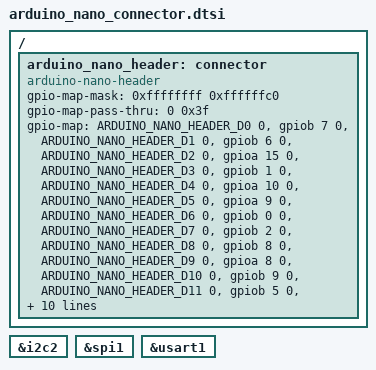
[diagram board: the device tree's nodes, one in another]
/*
 * Copyright (c) 2022 Joylab AG
 * SPDX-License-Identifier: Apache-2.0
 */

#include <zephyr/dt-bindings/gpio/arduino-nano-header.h>

/ {
	arduino_nano_header: connector {
		compatible = "arduino-nano-header";
		#gpio-cells = <2>;
		gpio-map-mask = <0xffffffff 0xffffffc0>;
		gpio-map-pass-thru = <0 0x3f>;
		gpio-map = <ARDUINO_NANO_HEADER_D0 0 &gpiob 7 0>,   /* D0 / UART-RX */
			   <ARDUINO_NANO_HEADER_D1 0 &gpiob 6 0>,   /* D1 / UART-TX */
			   <ARDUINO_NANO_HEADER_D2 0 &gpioa 15 0>,  /* D2 */
			   <ARDUINO_NANO_HEADER_D3 0 &gpiob 1 0>,   /* D3 */
			   <ARDUINO_NANO_HEADER_D4 0 &gpioa 10 0>,  /* D4 */
			   <ARDUINO_NANO_HEADER_D5 0 &gpioa 9 0>,   /* D5 */
			   <ARDUINO_NANO_HEADER_D6 0 &gpiob 0 0>,   /* D6 */
			   <ARDUINO_NANO_HEADER_D7 0 &gpiob 2 0>,   /* D7 */
			   <ARDUINO_NANO_HEADER_D8 0 &gpiob 8 0>,   /* D8 */
			   <ARDUINO_NANO_HEADER_D9 0 &gpioa 8 0>,   /* D9 */
			   <ARDUINO_NANO_HEADER_D10 0 &gpiob 9 0>,  /* D10 */
			   <ARDUINO_NANO_HEADER_D11 0 &gpiob 5 0>,  /* D11 / SPI-MOSI */
			   <ARDUINO_NANO_HEADER_D12 0 &gpiob 4 0>,  /* D12 / SPI-MISO */
			   <ARDUINO_NANO_HEADER_D13 0 &gpiob 3 0>,  /* D13 / SPI-SCK */
			   <ARDUINO_NANO_HEADER_D14 0 &gpioa 0 0>,  /* D14 / A0 */
			   <ARDUINO_NANO_HEADER_D15 0 &gpioa 1 0>,  /* D15 / A1 */
			   <ARDUINO_NANO_HEADER_D16 0 &gpioa 4 0>,  /* D16 / A2 */
			   <ARDUINO_NANO_HEADER_D17 0 &gpioa 5 0>,  /* D17 / A3 */
			   <ARDUINO_NANO_HEADER_D18 0 &gpioa 12 0>, /* D18 / A4 / I2C-SDA */
			   <ARDUINO_NANO_HEADER_D19 0 &gpioa 11 0>, /* D19 / A5 / I2C-SCL */
			   <ARDUINO_NANO_HEADER_D20 0 &gpioa 6 0>,  /* D20 / A6 */
			   <ARDUINO_NANO_HEADER_D21 0 &gpioa 7 0>;  /* D21 / A7 */
	};
};

arduino_nano_i2c: &i2c2 {};

arduino_nano_spi: &spi1 {};

arduino_nano_serial: &usart1 {};
